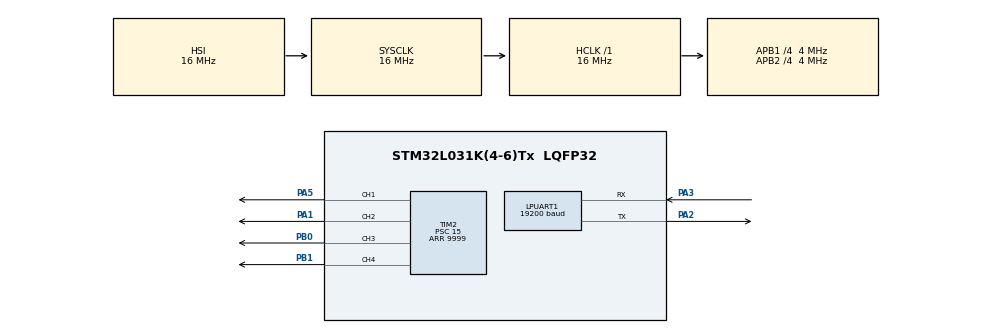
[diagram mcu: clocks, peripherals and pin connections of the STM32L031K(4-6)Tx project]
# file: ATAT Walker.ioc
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LPUART1.BaudRate=19200
LPUART1.WordLength=UART_WORDLENGTH_8B
Mcu.Family=STM32L0
Mcu.Name=STM32L031K(4-6)Tx
Mcu.Package=LQFP32
NVIC.LPUART1_IRQn=true\:0\:0\:false\:false\:true\:true\:true\:true
PA1.Signal=S_TIM2_CH2
PA13.Mode=Serial_Wire
PA13.Signal=SYS_SWDIO
PA14.Mode=Serial_Wire
PA14.Signal=SYS_SWCLK
PA2.Mode=Asynchronous
PA2.Signal=LPUART1_TX
PA3.Mode=Asynchronous
PA3.Signal=LPUART1_RX
PA5.Signal=S_TIM2_CH1
PB0.Signal=S_TIM2_CH3
PB1.Signal=S_TIM2_CH4
PC14-OSC32_IN.Mode=LSE-External-Oscillator
PC14-OSC32_IN.Signal=RCC_OSC32_IN
PC15-OSC32_OUT.Mode=LSE-External-Oscillator
PC15-OSC32_OUT.Signal=RCC_OSC32_OUT
ProjectManager.HeapSize=0x200
ProjectManager.StackSize=0x400
ProjectManager.TargetToolchain=STM32CubeIDE
RCC.AHBFreq_Value=16000000
RCC.APB1CLKDivider=RCC_HCLK_DIV4
RCC.APB1Freq_Value=4000000
RCC.APB1TimFreq_Value=8000000
RCC.APB2CLKDivider=RCC_HCLK_DIV4
RCC.APB2Freq_Value=4000000
RCC.APB2TimFreq_Value=8000000
RCC.HCLKFreq_Value=16000000
RCC.HSE_VALUE=8000000
RCC.HSI16_VALUE=16000000
RCC.HSI_VALUE=16000000
RCC.MSI_VALUE=2097000
RCC.SYSCLKFreq_VALUE=16000000
RCC.SYSCLKSource=RCC_SYSCLKSOURCE_HSI
RCC.VCOOutputFreq_Value=48000000
SH.S_TIM2_CH1.0=TIM2_CH1,PWM Generation1 CH1
SH.S_TIM2_CH2.0=TIM2_CH2,PWM Generation2 CH2
SH.S_TIM2_CH3.0=TIM2_CH3,PWM Generation3 CH3
SH.S_TIM2_CH4.0=TIM2_CH4,PWM Generation4 CH4
TIM2.AutoReloadPreload=TIM_AUTORELOAD_PRELOAD_DISABLE
TIM2.Channel-PWM\ Generation1\ CH1=TIM_CHANNEL_1
TIM2.Channel-PWM\ Generation2\ CH2=TIM_CHANNEL_2
TIM2.Channel-PWM\ Generation3\ CH3=TIM_CHANNEL_3
TIM2.Channel-PWM\ Generation4\ CH4=TIM_CHANNEL_4
TIM2.Period=9999
TIM2.Prescaler=15
VP_TIM2_VS_ClockSourceINT.Mode=Internal
board=custom

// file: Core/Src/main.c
/* USER CODE BEGIN Header */
/**
  ******************************************************************************
  * @file           : main.c
  * @brief          : Main program body
  ******************************************************************************
  * @attention
  *
  * Copyright (c) 2024 STMicroelectronics.
  * All rights reserved.
  *
  * This software is licensed under terms that can be found in the LICENSE file
  * in the root directory of this software component.
  * If no LICENSE file comes with this software, it is provided AS-IS.
  *
  ******************************************************************************
  */
/* USER CODE END Header */
#include "main.h"
#include <string.h>
void calc_degree(int32_t angle_end, int motor);
void motion();

UART_HandleTypeDef hlpuart1;

int32_t CCR_reg = 0;
//int32_t CCR_reg2 = 0;
//int32_t CCR_reg3 = 0;
//int32_t CCR_reg4 = 0;
int32_t Q0[] = {0, 90, 180, 270};
int32_t Q1[] = {90, 180, 90, 0};
int32_t Q2[] = {0, 45, 90, 90, 90, 90, 45, 0};
int32_t Q3[] = {45, 45, 45, 90, 120, 135, 90, 45};
int32_t* QMat[] = {Q0, Q1, Q2, Q3};
int32_t currState[] = {0,0,0,0};
int32_t receivedNumber = 0;
uint8_t flag = 0;
uint8_t Degree[]  = {0,0};

TIM_HandleTypeDef htim2;

void SystemClock_Config(void);
static void MX_GPIO_Init(void);
static void MX_TIM2_Init(void);
static void MX_LPUART1_UART_Init(void);

int main(void)
{

  /* USER CODE BEGIN 1 */
	//int32_t CH1_DC = 0;

  /* USER CODE END 1 */

  /* MCU Configuration--------------------------------------------------------*/

  /* Reset of all peripherals, Initializes the Flash interface and the Systick. */
  HAL_Init();

  /* Configure the system clock */
  SystemClock_Config();

  /* Initialize all configured peripherals */
  MX_GPIO_Init();
  MX_TIM2_Init();
  MX_LPUART1_UART_Init();
  /* USER CODE BEGIN 2 */
  HAL_TIM_PWM_Start(&htim2, TIM_CHANNEL_1);
  HAL_TIM_PWM_Start(&htim2, TIM_CHANNEL_2);
  HAL_TIM_PWM_Start(&htim2, TIM_CHANNEL_3);
  HAL_TIM_PWM_Start(&htim2, TIM_CHANNEL_4);
  HAL_UART_Receive_IT(&hlpuart1, Degree, sizeof(Degree));
  CCR_reg = 0;
//  CCR_reg2 = 0;
//  CCR_reg3 = 0;
//  CCR_reg4 = 0;
//  __HAL_TIM_SET_COMPARE(&htim2, TIM_CHANNEL_1, CCR_reg);
//  __HAL_TIM_SET_COMPARE(&htim2, TIM_CHANNEL_2, CCR_reg2);
//  __HAL_TIM_SET_COMPARE(&htim2, TIM_CHANNEL_3, CCR_reg3);
//  __HAL_TIM_SET_COMPARE(&htim2, TIM_CHANNEL_4, CCR_reg4);
//  CCR_reg = ((90) / 0.18 + 250); //0.27
//  __HAL_TIM_SET_COMPARE(&htim2, TIM_CHANNEL_4, CCR_reg);
//  __HAL_TIM_SET_COMPARE(&htim2, TIM_CHANNEL_3, CCR_reg);

  /* USER CODE END 2 */

  /* Infinite loop */
  while (1)
  {
//		if (flag) calc_degree(Q0[1], 0);
//		if (flag) calc_degree(Q0[2], 0);
//		if (flag) calc_degree(Q0[3], 0);
//		if (flag) calc_degree(Q0[2], 0);
//		if (flag) calc_degree(Q0[1], 0);
//	  CCR_reg = currState[motor] / 0.27 + 250; //0.27
//	  __HAL_TIM_SET_COMPARE(&htim2, TIM_CHANNEL_4, CCR_reg);
	  //calc_degree(180, 3);
//	  if(flag){
				  for(int i = 0; i < 8; i++){
					  CCR_reg = ((QMat[3][i]) / 0.18 + 250);
					  __HAL_TIM_SET_COMPARE(&htim2, TIM_CHANNEL_4, CCR_reg);
					  CCR_reg = ((QMat[2][i]) / 0.18 + 250);
					  __HAL_TIM_SET_COMPARE(&htim2, TIM_CHANNEL_1, CCR_reg);
					  HAL_Delay(1000);
				  }
//	  CCR_reg = ((90) / 0.18 + 250);
//	  __HAL_TIM_SET_COMPARE(&htim2, TIM_CHANNEL_4, CCR_reg);
//	  __HAL_TIM_SET_COMPARE(&htim2, TIM_CHANNEL_1, CCR_reg);
//	  }
//	  			  CCR_reg = ((45) / 0.18 + 250);
//	  			  __HAL_TIM_SET_COMPARE(&htim2, TIM_CHANNEL_4, CCR_reg);
//	  			  CCR_reg = ((45) / 0.18 + 250);
//	  			  __HAL_TIM_SET_COMPARE(&htim2, TIM_CHANNEL_3, CCR_reg);
  }
}

//void calc_degree(int32_t angle_end, int motor) {
//
//    float duration = 5;
//    float angle_step = (angle_end - currState[motor]) / 100.0;  // 100 steps for smooth movement
//    float time_per_step = duration / 100.0;  // 5 seconds divided by 100 steps
//
//    for (int i = 0; i < 100; i++) {
//        // Calculate the new CCR value based on current angle
//        CCR_reg = currState[motor] / 0.27 + 250;
//
//        // Set the motor position via PWM (update the timer compare register)
//        __HAL_TIM_SET_COMPARE(&htim2, TIM_CHANNEL_1, CCR_reg);
//
//        // Increment the angle
//        currState[motor] += angle_step;
//
//        // Wait before the next step (blocking delay for simplicity)
//        HAL_Delay(time_per_step * 1000);  // HAL_Delay takes milliseconds
//    }
//}
//
//void motion() {
//	//if (flag) calc_degree(Q0[0], 0);
//    if (flag) calc_degree(Q0[1], 0);
//    if (flag) calc_degree(Q0[2], 0);
//    if (flag) calc_degree(Q0[3], 0);
//    if (flag) calc_degree(Q0[2], 0);
//    if (flag) calc_degree(Q0[1], 0);
//}

void calc_degree(int32_t angle_end, int motor) {

    float duration = 5;
    float angle_step = (angle_end - currState[motor]) / 100.0;  // 100 steps for smooth movement
    if(angle_step == 0)return;
    float time_per_step = duration / 100.0;  // 5 seconds divided by 100 steps

    for (int i = 0; i < 100; i++) {
        // Calculate the new CCR value based on current angle
        CCR_reg = currState[motor] / 0.18 + 250; //0.27

        // Set the motor position via PWM (update the timer compare register)
        switch (motor) {
            case 0:
                __HAL_TIM_SET_COMPARE(&htim2, TIM_CHANNEL_1, CCR_reg);
                break; // Add break to prevent fall-through
            case 1:
                __HAL_TIM_SET_COMPARE(&htim2, TIM_CHANNEL_2, CCR_reg);
                break;
            case 2:
                __HAL_TIM_SET_COMPARE(&htim2, TIM_CHANNEL_3, CCR_reg);
                break;
            case 3:
                __HAL_TIM_SET_COMPARE(&htim2, TIM_CHANNEL_4, CCR_reg);
                break;
            default:;
        }

        // Increment the angle
        currState[motor] += angle_step;
//        if (currState[motor] < angle_end && currState[motor] + angle_step <= 270) {
//        	currState[motor] += angle_step;
//        } else if(currState[motor] - angle_step >= 0){
//        	currState[motor] -= angle_step;
//        }

        // Wait before the next step (blocking delay for simplicity)
        HAL_Delay(time_per_step * 1000);  // HAL_Delay takes milliseconds
    }
}

void HAL_UART_RxCpltCallback(UART_HandleTypeDef *huart) {
  //if (huart->Instance == LPUART1) { // Ensure this matches your UART instance
      // Combine bytes into a 16-bit number
//	for (int i = 0; i < 3; i++) {
//		if (Degree[i] < '0' || Degree[i] > '9') {
//			// Handle error: invalid input
//			return;
//		}
//	}

//	uint16_t Q0[] = {0, 270, 180};
//	uint16_t Q1[] = {90, 180, 90};
//	uint16_t Q2[] = {180, 90, 0};
//	uint16_t Q3[] = {270, 0, 270};
//	uint16_t* QMat[] = {Q0, Q1, Q2, Q3};
//
////	receivedNumber = (Degree[0] - 48) * 100 + (Degree[1] - 48) * 10 + (Degree[2] - 48);
	receivedNumber = (Degree[0] - 48);
	if(receivedNumber == 0){
		flag = 1;
	}else{
		flag = 0;
		__HAL_TIM_SET_COMPARE(&htim2, TIM_CHANNEL_1, 0);
	}
//    if (receivedNumber >= 0 && receivedNumber < 4) { // Ensure it's within bounds
//        CCR_reg = QMat[receivedNumber][0] / 0.27 + 250; // Access the value
//        CCR_reg2 = QMat[receivedNumber][0] / 0.27 + 250; // Access the value
//        CCR_reg3 = QMat[receivedNumber][0] / 0.27 + 250; // Access the value
//        CCR_reg4 = QMat[receivedNumber][0] / 0.27 + 250; // Access the value
//        __HAL_TIM_SET_COMPARE(&htim2, TIM_CHANNEL_1, CCR_reg);
//        __HAL_TIM_SET_COMPARE(&htim2, TIM_CHANNEL_2, CCR_reg2);
//        __HAL_TIM_SET_COMPARE(&htim2, TIM_CHANNEL_3, CCR_reg3);
//        __HAL_TIM_SET_COMPARE(&htim2, TIM_CHANNEL_4, CCR_reg4);
//    }
//
//
	memset(Degree, 0, sizeof(Degree));
	HAL_UART_Receive_IT(&hlpuart1, Degree, sizeof(Degree));
}

//==========================================================
//    newPos = moveJoint(Q0[2], Q0[1]);
//    CCR_regn = newPos / 0.27 + 250;
//	uint16_t moveJoint( uint16_t startPos, uint16_t endPos) {
//		pos = startPos;
//		if (startPos < endPos) {
//			pos += 10;
//		} else if (startPos > endPOs){
//			pos -= 10;
//		}
//		return pos;
//	}
//==========================================================

void SystemClock_Config(void)
{
  RCC_OscInitTypeDef RCC_OscInitStruct = {0};
  RCC_ClkInitTypeDef RCC_ClkInitStruct = {0};
  RCC_PeriphCLKInitTypeDef PeriphClkInit = {0};

  /** Configure the main internal regulator output voltage
  */
  __HAL_PWR_VOLTAGESCALING_CONFIG(PWR_REGULATOR_VOLTAGE_SCALE1);

  /** Initializes the RCC Oscillators according to the specified parameters
  * in the RCC_OscInitTypeDef structure.
  */
  RCC_OscInitStruct.OscillatorType = RCC_OSCILLATORTYPE_HSI;
  RCC_OscInitStruct.HSIState = RCC_HSI_ON;
  RCC_OscInitStruct.HSICalibrationValue = RCC_HSICALIBRATION_DEFAULT;
  RCC_OscInitStruct.PLL.PLLState = RCC_PLL_NONE;
  if (HAL_RCC_OscConfig(&RCC_OscInitStruct) != HAL_OK)
  {
    Error_Handler();
  }

  /** Initializes the CPU, AHB and APB buses clocks
  */
  RCC_ClkInitStruct.ClockType = RCC_CLOCKTYPE_HCLK|RCC_CLOCKTYPE_SYSCLK
                              |RCC_CLOCKTYPE_PCLK1|RCC_CLOCKTYPE_PCLK2;
  RCC_ClkInitStruct.SYSCLKSource = RCC_SYSCLKSOURCE_HSI;
  RCC_ClkInitStruct.AHBCLKDivider = RCC_SYSCLK_DIV1;
  RCC_ClkInitStruct.APB1CLKDivider = RCC_HCLK_DIV4;
  RCC_ClkInitStruct.APB2CLKDivider = RCC_HCLK_DIV4;

  if (HAL_RCC_ClockConfig(&RCC_ClkInitStruct, FLASH_LATENCY_0) != HAL_OK)
  {
    Error_Handler();
  }
  PeriphClkInit.PeriphClockSelection = RCC_PERIPHCLK_LPUART1;
  PeriphClkInit.Lpuart1ClockSelection = RCC_LPUART1CLKSOURCE_PCLK1;
  if (HAL_RCCEx_PeriphCLKConfig(&PeriphClkInit) != HAL_OK)
  {
    Error_Handler();
  }
}

static void MX_LPUART1_UART_Init(void)
{

  hlpuart1.Instance = LPUART1;
  hlpuart1.Init.BaudRate = 19200;
  hlpuart1.Init.WordLength = UART_WORDLENGTH_8B;
  hlpuart1.Init.StopBits = UART_STOPBITS_1;
  hlpuart1.Init.Parity = UART_PARITY_NONE;
  hlpuart1.Init.Mode = UART_MODE_TX_RX;
  hlpuart1.Init.HwFlowCtl = UART_HWCONTROL_NONE;
  hlpuart1.Init.OneBitSampling = UART_ONE_BIT_SAMPLE_DISABLE;
  hlpuart1.AdvancedInit.AdvFeatureInit = UART_ADVFEATURE_NO_INIT;
  if (HAL_UART_Init(&hlpuart1) != HAL_OK)
  {
    Error_Handler();
  }

}

static void MX_TIM2_Init(void)
{

  TIM_ClockConfigTypeDef sClockSourceConfig = {0};
  TIM_MasterConfigTypeDef sMasterConfig = {0};
  TIM_OC_InitTypeDef sConfigOC = {0};

  htim2.Instance = TIM2;
  htim2.Init.Prescaler = 15;
  htim2.Init.CounterMode = TIM_COUNTERMODE_UP;
  htim2.Init.Period = 9999;
  htim2.Init.ClockDivision = TIM_CLOCKDIVISION_DIV1;
  htim2.Init.AutoReloadPreload = TIM_AUTORELOAD_PRELOAD_DISABLE;
  if (HAL_TIM_Base_Init(&htim2) != HAL_OK)
  {
    Error_Handler();
  }
  sClockSourceConfig.ClockSource = TIM_CLOCKSOURCE_INTERNAL;
  if (HAL_TIM_ConfigClockSource(&htim2, &sClockSourceConfig) != HAL_OK)
  {
    Error_Handler();
  }
  if (HAL_TIM_PWM_Init(&htim2) != HAL_OK)
  {
    Error_Handler();
  }
  sMasterConfig.MasterOutputTrigger = TIM_TRGO_RESET;
  sMasterConfig.MasterSlaveMode = TIM_MASTERSLAVEMODE_DISABLE;
  if (HAL_TIMEx_MasterConfigSynchronization(&htim2, &sMasterConfig) != HAL_OK)
  {
    Error_Handler();
  }
  sConfigOC.OCMode = TIM_OCMODE_PWM1;
  sConfigOC.Pulse = 0;
  sConfigOC.OCPolarity = TIM_OCPOLARITY_HIGH;
  sConfigOC.OCFastMode = TIM_OCFAST_DISABLE;
  if (HAL_TIM_PWM_ConfigChannel(&htim2, &sConfigOC, TIM_CHANNEL_1) != HAL_OK)
  {
    Error_Handler();
  }
  if (HAL_TIM_PWM_ConfigChannel(&htim2, &sConfigOC, TIM_CHANNEL_2) != HAL_OK)
  {
    Error_Handler();
  }
  if (HAL_TIM_PWM_ConfigChannel(&htim2, &sConfigOC, TIM_CHANNEL_3) != HAL_OK)
  {
    Error_Handler();
  }
  if (HAL_TIM_PWM_ConfigChannel(&htim2, &sConfigOC, TIM_CHANNEL_4) != HAL_OK)
  {
    Error_Handler();
  }
  HAL_TIM_MspPostInit(&htim2);

}

static void MX_GPIO_Init(void)
{

  /* GPIO Ports Clock Enable */
  __HAL_RCC_GPIOC_CLK_ENABLE();
  __HAL_RCC_GPIOA_CLK_ENABLE();
  __HAL_RCC_GPIOB_CLK_ENABLE();

}

void Error_Handler(void)
{
  __disable_irq();
  while (1)
  {
  }
}
